# cm4f register map
Registers are 32-bit, read-write, no defined reset value unless marked. A register's access mark holds for its fields unless they carry their own. Offsets are from the block's base; [hi:lo] are bit positions; lines under a group give offsets from that group; {n}, {i} and the like mark numbered series; 'fields as' and 'values as' point back to an identical list.

## MPU — Memory Protection Unit
Base 0xE000ED90; register names take the prefix MPU_
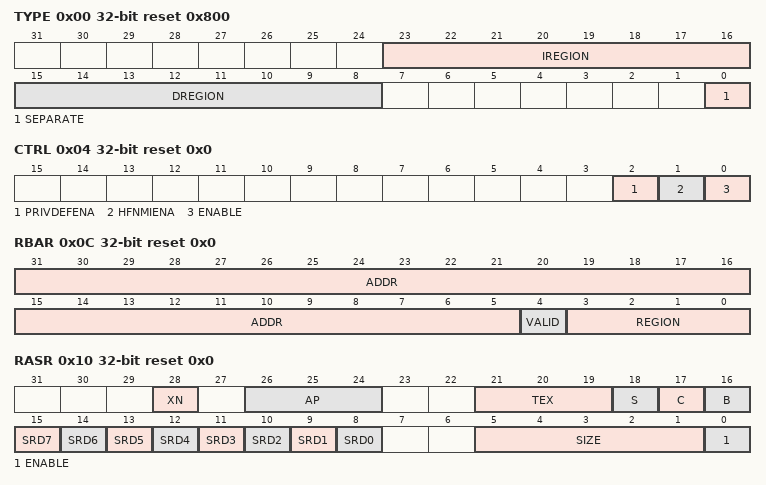
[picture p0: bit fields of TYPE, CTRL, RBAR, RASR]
0x00 TYPE ro reset 0x800 — MPU Type Register
  [23:16] IREGION — Indicates the number of supported MPU instruction regions. Always contains 0x0: the MPU memory map is unified and is described by the DREGION field.
  [15:8] DREGION — Indicates the number of supported MPU data regions depending on your implementation.
  [0] SEPARATE — Indicates support for unified or separate instruction and data memory maps.
    0=Unified (Only unified memory maps are supported.)
0x04 CTRL reset 0x0 — MPU Control Register
  [2] PRIVDEFENA — Enables privileged software access to the default memory map.
  [1] HFNMIENA — Enables the operation of MPU during hard fault, NMI, and FAULTMASK handlers.
  [0] ENABLE — Enables the optional MPU.
0x08 RNR reset 0x0 — MPU Region Number Register
  [7:0] REGION — Indicates the MPU region referenced by the MPU_RBAR and MPU_RASR registers.
0x0C RBAR reset 0x0 — MPU Region Base Address Register
  [31:5] ADDR — The ADDR field is bits[31:N] of the MPU_RBAR. The region size, as specified by the SIZE field in the MPU_RASR, defines the value of N: N = Log2(Region size in bytes). If the region size is configured to 4GB, in the MPU_RASR, there is no valid ADDR field. In this case, the region occupies the complete memory map, and the base address is 0x00000000. The base address is aligned to the size of the region. For example, a 64KB region must be aligned on a multiple of 64KB, for example, at 0x00010000 or 0x00020000.
  [4] VALID — MPU Region number valid bit. Depending on your implementation, this has the following effect: 0 - either updates the base address for the region specified by MPU_RNR or ignores the value of the REGION field. 1 - either updates the value of the MPU_RNR to the value of the REGION field or updates the base address for the region specified in the REGION field.
  [3:0] REGION — On Write, see the VALID field. On read, specifies the region number.
0x10 RASR reset 0x0 — MPU Region Base Attribute and Size Register
  [28] XN — Instruction access disable bit
    0=I_Enabled (Instruction fetches enabled.); 1=I_Disabled (Instruction fetches disabled.)
  [26:24] AP — Access permission field
    0=No_Access (All accesses generate a permission fault.); 1=Privileged_RW (Access from privileged software only.); 2=Unpriviledged_RO (Writes by unprivileged software generates a permission fault.); 3=Full_Access; 5=Privileged_RO (Reads by privileged software only.); 6=Read_Only by privileged or unprivileged software; 7=Read_Only by privileged or unprivileged software
  [21:19] TEX — Memory access attribute.
  [18] S — Shareable bit. Applies to Normal memory only.
  [17] C — Memory access attribute.
  [16] B — Memory access attribute.
  [15] SRD7 — Subregion disable bits.
  [14] SRD6 — Subregion disable bits.
  [13] SRD5 — Subregion disable bits.
  [n+8] SRD{n} (n=0..4) — Subregion disable bits
  [5:1] SIZE — Specifies the size of the MPU protection region. Minimum value is 4. The Region size is defined as (Region size in bytes) = 2^(SIZE+1)
  [0] ENABLE — Region enable bit.
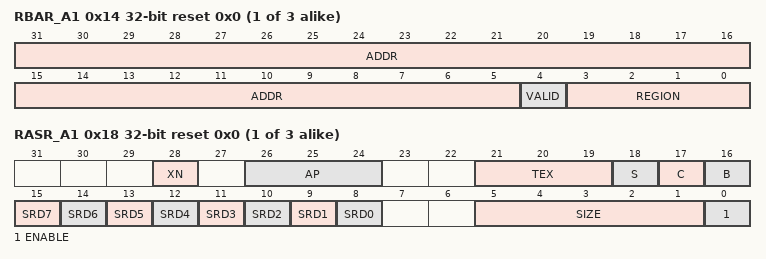
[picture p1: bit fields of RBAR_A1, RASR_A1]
{0xC+8i} RBAR_A{i} reset 0x0 (i=1..3) — Uses (MPU_RNR[7:2]<<2) + {i}
  fields as RBAR
{0x10+8i} RASR_A{i} reset 0x0 (i=1..3) — Uses (MPU_RNR[7:2]<<2) + {i}
  fields as RASR

## Debug
Base 0xE000ED00
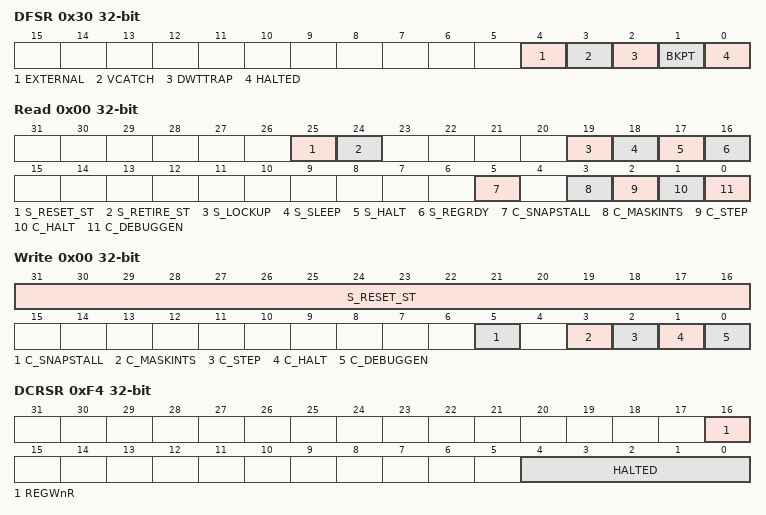
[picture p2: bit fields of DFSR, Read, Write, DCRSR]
0x30 DFSR — Debug Fault Status Register
  [4] EXTERNAL — An asynchronous exception generated due to the assertion of EDBGRQ.
  [3] VCATCH — Vector catch triggered. Corresponding FSR will contain the primary cause of the exception.
  [2] DWTTRAP — Data Watchpoint and Trace trap. Indicates that the core halted due to at least one DWT trap event.
  [1] BKPT — BKPT instruction executed or breakpoint match in FPB.
  [0] HALTED
0xF0 DHCSR group — Debug Halting Control and Status Register
  0x00 Read ro
    [25] S_RESET_ST, [24] S_RETIRE_ST, [19] S_LOCKUP, [18] S_SLEEP, [17] S_HALT, [16] S_REGRDY, [5] C_SNAPSTALL, [3] C_MASKINTS, [2] C_STEP, [1] C_HALT, [0] C_DEBUGGEN
  0x00 Write wo (alternate view of DHCSR_Read)
    [31:16] S_RESET_ST — Debug Key. The value 0xA05F must be written to enable write accesses to bits [15:0], otherwise the write access will be ignored. Read behavior of bits [31:16] is as listed below.
    [5] C_SNAPSTALL
    [3] C_MASKINTS
    [2] C_STEP
    [1] C_HALT
    [0] C_DEBUGGEN
0xF4 DCRSR wo — Debug Core Register Selector Register: The DCRSR write-only register generates a handshake to the core to transfer the selected register to/from the DCRDR. The DHCSR S_REGRDY bit is cleared when the DCRSR is written, and remains clear until the core transaction completes. This register is only accessible from Debug state.
  [16] REGWnR
    1=Write; 0=Read
  [4:0] HALTED
    {v}=Register_{v} (v=0..12); 13=Current_SP; 14=Link_Rregister; 15=Debug_Return_Address; 16=xPSR; 17=MSP; 18=PSP; 19=CONTROL_FAULTMASK_BASEPRI_PRIMASK
0xF8 DCRDR — Debug Core Register Data Register
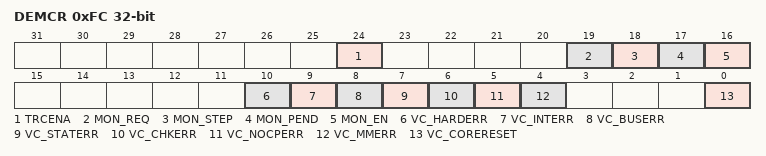
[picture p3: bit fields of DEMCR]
0xFC DEMCR — Debug Exception and Monitor Control Register
  [24] TRCENA, [19] MON_REQ, [18] MON_STEP, [17] MON_PEND, [16] MON_EN, [10] VC_HARDERR, [9] VC_INTERR, [8] VC_BUSERR, [7] VC_STATERR, [6] VC_CHKERR, [5] VC_NOCPERR, [4] VC_MMERR, [0] VC_CORERESET

## DWT — Data Watchpoint Trace
Base 0xE0001000
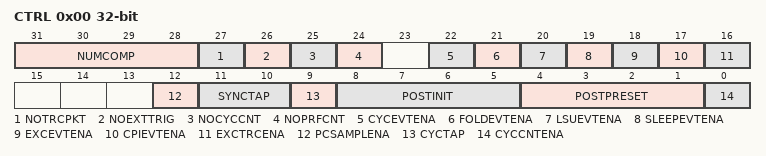
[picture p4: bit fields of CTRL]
0x00 CTRL — Control Register
  [31:28] NUMCOMP — Number of comparators
  [27] NOTRCPKT — No trace sampling and exception tracing
  [26] NOEXTTRIG — No external match signals
  [25] NOCYCCNT — No cycle counter
  [24] NOPRFCNT — No profiling counters
  [22] CYCEVTENA — enable Cycle count event
  [21] FOLDEVTENA — enable Folded instruction count event
  [20] LSUEVTENA — enable Load Store Unit (LSU) count event
  [19] SLEEPEVTENA — enable Sleep count event
  [18] EXCEVTENA — enable interrupt overhead event
  [17] CPIEVTENA — enable CPI count event
  [16] EXCTRCENA — enable interrupt event tracing
  [12] PCSAMPLENA — enable POSTCNT as timer for PC sample packets
  [11:10] SYNCTAP — ???
  [9] CYCTAP — ???
  [8:5] POSTINIT — ???
  [4:1] POSTPRESET — ???
  [0] CYCCNTENA — enable cycle counter
0x04 CYCCNT — Cycle Count Register
0x08 CPICNT — CPI Count Register
0x0C EXCCNT — Exception Overhead Count Register
0x10 SLEEPCNT — Sleep Count Register
0x14 LSUCNT — LSU Count Register
0x18 FOLDCNT — Folded-instruction Count Register
0x1C PCSR — Program Counter Sample Register
{0x20+0x10*i} COMP{i} (i=0..3) — Comparator Register {i}
{0x24+0x10*i} MASK{i} (i=0..3) — Mask Register {i}
{0x28+0x10*i} FUNCTION{i} (i=0..3) — Function Register {i}

## Notices in the file
Copyright (C) 2016 AdaCore
